# APM32F403 register map
File version: 1.0
CPU: CM4 r1p0, little endian, no MPU, no FPU, 4 interrupt priority bits
Registers are 32-bit, read-write, reset 0x0 unless marked. A register's access mark holds for its fields unless they carry their own. Offsets are from the block's base; [hi:lo] are bit positions; {n}, {i} and the like mark numbered series.

## FMC — Flash memory controller
Base 0x40022000
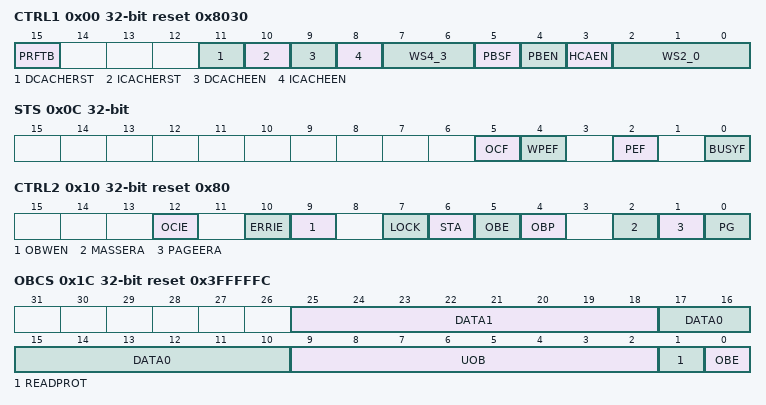
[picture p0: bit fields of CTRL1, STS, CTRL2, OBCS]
0x00 CTRL1 access per field reset 0x8030 — Flash access control register
  [15] PRFTB rw — Prefetch Control
  [11] DCACHERST rw — Data cache reset
  [10] ICACHERST wo — Instruction cache reset
  [9] DCACHEEN rw — Data cache enable
  [8] ICACHEEN rw — Instruction cache enable
  [7:6] WS4_3 rw — Wait State Configure
  [5] PBSF ro — Prefetch Buffer Status Flag
  [4] PBEN rw — Prefetch Buffer Enable
  [3] HCAEN rw — Flash Half Cycle Access Enable
  [2:0] WS2_0 rw — Wait State Configure
0x04 KEY wo — Flash key register
0x08 OBKEY wo — Option byte key register
  [31:0] OBKEY — Option byte key
0x0C STS access per field — Status register
  [5] OCF rw — End of operation
  [4] WPEF rw — Write protection error
  [2] PEF rw — Programming error
  [0] BUSYF ro — Busy
0x10 CTRL2 reset 0x80 — Control register
  [12] OCIE — End of operation interrupt enable
  [10] ERRIE — Error interrupt enable
  [9] OBWEN — Option bytes write enable
  [7] LOCK
  [6] STA — Start
  [5] OBE — Option byte erase
  [4] OBP — Option byte programming
  [2] MASSERA — Mass Erase
  [1] PAGEERA — Page Erase
  [0] PG — Programming
0x14 ADDR wo — Flash address register
  [31:0] ADDR — Flash Address
0x1C OBCS ro reset 0x3FFFFFC — Option byte register
  [25:18] DATA1
  [17:10] DATA0
  [9:2] UOB — User Option Byte
  [1] READPROT — Read protection
  [0] OBE — Option byte error
0x20 WRTPROT ro reset 0xFFFFFFFF — Write protection register
  [31:0] WRTPROT — Write protect

## CRC — Cryptographic processor
Base 0x40023000
0x00 DATA reset 0xFFFFFFFF
0x04 INDATA — Independent Data register
  [7:0] INDATA
0x08 CTRL wo — Control register
  [0] RST — Reset CRC Calculation Unit

## AFIO — Alternate function I/O
Base 0x40010000
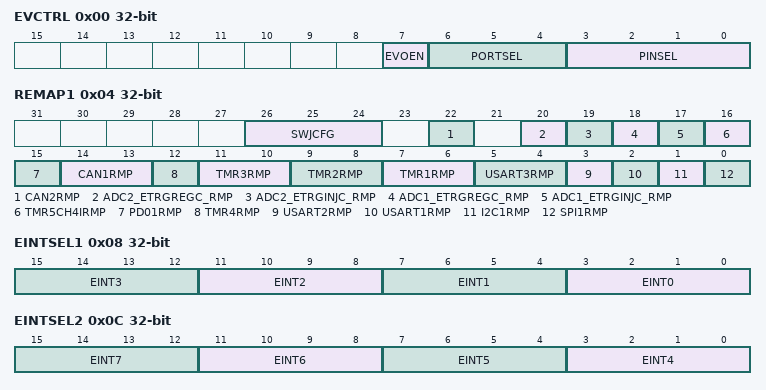
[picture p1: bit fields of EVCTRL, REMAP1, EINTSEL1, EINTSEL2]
0x00 EVCTRL — Event control register
  [7] EVOEN — Event Output Enable
  [6:4] PORTSEL — Portx Select
  [3:0] PINSEL — Portx Piny Select
0x04 REMAP1 access per field — Alternate function IO remap and Serial wire JTAG configuration register
  [26:24] SWJCFG wo — Serial wire JTAG configuration
  [22] CAN2RMP rw — CAN2 alternate function remapping
  [20] ADC2_ETRGREGC_RMP rw — ADC 2 external trigger regular conversion remapping
  [19] ADC2_ETRGINJC_RMP rw — ADC 2 external trigger injected conversion remapping
  [18] ADC1_ETRGREGC_RMP rw — ADC 1 external trigger regular conversion remapping
  [17] ADC1_ETRGINJC_RMP rw — ADC 1 External trigger injected conversion remapping
  [16] TMR5CH4IRMP rw — TMR5 channel4 internal remap
  [15] PD01RMP rw — Port D0/Port D1 mapping on OSC_IN/OSC_OUT
  [14:13] CAN1RMP rw — CAN1 alternate function remapping
  [12] TMR4RMP rw — TMR4 remapping
  [11:10] TMR3RMP rw — TMR3 remapping
  [9:8] TMR2RMP rw — TMR2 remapping
  [7:6] TMR1RMP rw — TMR1 remapping
  [5:4] USART3RMP rw — USART3 remapping
  [3] USART2RMP rw — USART2 remapping
  [2] USART1RMP rw — USART1 remapping
  [1] I2C1RMP rw — I2C1 remapping
  [0] SPI1RMP rw — SPI1 remapping
0x08 EINTSEL1 — External interrupt configuration register1
  [4n+3:4n] EINT{n} (n=0..3) — EINT {n} configuration
0x0C EINTSEL2 — External interrupt configuration register2
  [4n-13:4n-16] EINT{n} (n=4..7) — EINT {n} configuration
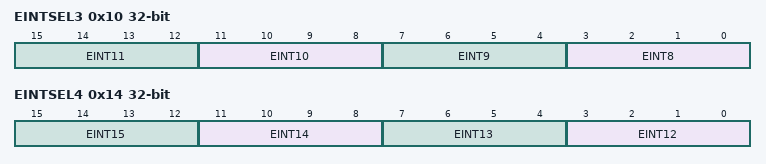
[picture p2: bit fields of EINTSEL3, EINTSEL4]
0x10 EINTSEL3 — External interrupt configuration register3
  [4n-29:4n-32] EINT{n} (n=8..11) — EINT {n} configuration
0x14 EINTSEL4 — External interrupt configuration register4
  [4n-45:4n-48] EINT{n} (n=12..15) — EINT {n} configuration

## DBGMCU — Debug support
Base 0xE0042000
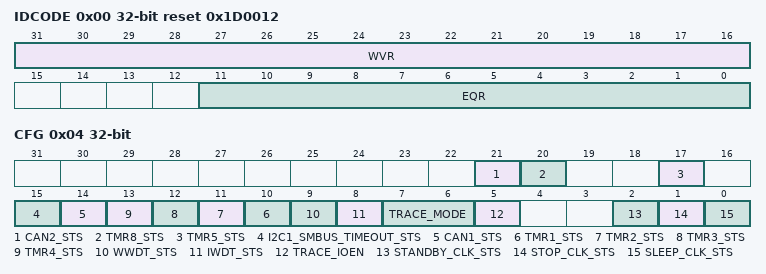
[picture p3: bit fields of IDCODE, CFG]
0x00 IDCODE ro reset 0x1D0012
  [31:16] WVR — Wafer Version Recognition
  [11:0] EQR — Equipment Recognition
0x04 CFG — Control Register
  [21] CAN2_STS — Configure CAN2 Work Status When Core Is in Halted
  [20] TMR8_STS — ConfigureTimer Work Status When Core Is in Halted
  [17] TMR5_STS — ConfigureTimer Work Status When Core Is in Halted
  [15] I2C1_SMBUS_TIMEOUT_STS — Configure I2C1_SMBUS_TIMEOUT Work Status When Core Is in Halted
  [14] CAN1_STS — Configure CAN1 Work Status When Core Is in Halted
  [n+9] TMR{n}_STS (n=1..4) — Configure Timer Work Status When Core Is in Halted
  [9] WWDT_STS — Configure Window Watchdog Work Status When Core Is in Halted
  [8] IWDT_STS — Configure Independent Watchdog Work Status When Core Is in Halted
  [7:6] TRACE_MODE — Trace Debug Pin Mode Configure
  [5] TRACE_IOEN — Trace Debug Pin Enable
  [2] STANDBY_CLK_STS — Configure clock status when MCU is debugged in standby mode
  [1] STOP_CLK_STS — Configure clock status when MCU is debugged in stop mode
  [0] SLEEP_CLK_STS — Configure clock status when MCU is debugged in sleep mode
